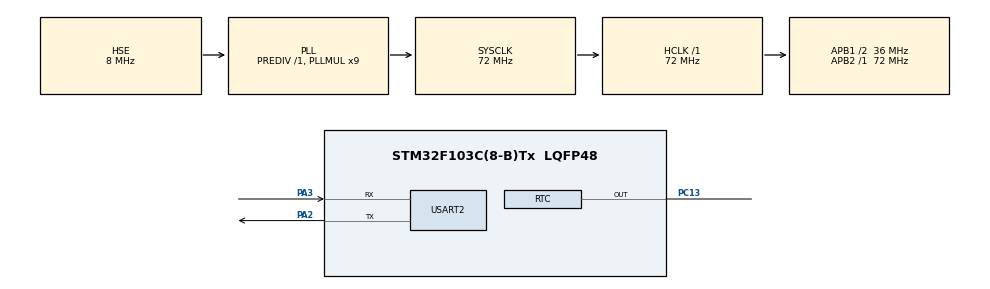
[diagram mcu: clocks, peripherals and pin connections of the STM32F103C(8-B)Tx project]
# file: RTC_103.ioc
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Mcu.Family=STM32F1
Mcu.Name=STM32F103C(8-B)Tx
Mcu.Package=LQFP48
NVIC.PriorityGroup=NVIC_PRIORITYGROUP_4
NVIC.RTC_Alarm_IRQn=true\:0\:0\:false\:false\:true\:true\:true
PA13.Mode=Serial_Wire
PA13.Signal=SYS_JTMS-SWDIO
PA14.Mode=Serial_Wire
PA14.Signal=SYS_JTCK-SWCLK
PA2.Mode=Asynchronous
PA2.Signal=USART2_TX
PA3.Mode=Asynchronous
PA3.Signal=USART2_RX
PC13-TAMPER-RTC.Mode=RTC OUT
PC13-TAMPER-RTC.Signal=RTC_OUT
PC14-OSC32_IN.Mode=LSE-External-Oscillator
PC14-OSC32_IN.Signal=RCC_OSC32_IN
PC15-OSC32_OUT.Mode=LSE-External-Oscillator
PC15-OSC32_OUT.Signal=RCC_OSC32_OUT
PD0-OSC_IN.Mode=HSE-External-Oscillator
PD0-OSC_IN.Signal=RCC_OSC_IN
PD1-OSC_OUT.Mode=HSE-External-Oscillator
PD1-OSC_OUT.Signal=RCC_OSC_OUT
ProjectManager.HeapSize=0x200
ProjectManager.StackSize=0x400
ProjectManager.TargetToolchain=STM32CubeIDE
RCC.AHBFreq_Value=72000000
RCC.APB1CLKDivider=RCC_HCLK_DIV2
RCC.APB1Freq_Value=36000000
RCC.APB1TimFreq_Value=72000000
RCC.APB2Freq_Value=72000000
RCC.APB2TimFreq_Value=72000000
RCC.HCLKFreq_Value=72000000
RCC.PLLMUL=RCC_PLL_MUL9
RCC.PLLSourceVirtual=RCC_PLLSOURCE_HSE
RCC.SYSCLKFreq_VALUE=72000000
RCC.SYSCLKSource=RCC_SYSCLKSOURCE_PLLCLK
RCC.USBFreq_Value=72000000
RTC.Date=21
RTC.Format=RTC_FORMAT_BIN
RTC.Hours=14
RTC.Hours_A-RTC\ OUT=14
RTC.Minutes=5
RTC.Minutes_A-RTC\ OUT=6
RTC.Month=RTC_MONTH_OCTOBER
RTC.OutPut=RTC_OUTPUTSOURCE_ALARM
RTC.Seconds=50
RTC.Seconds_A-RTC\ OUT=5
RTC.WeekDay=RTC_WEEKDAY_THURSDAY
RTC.Year=21
USART2.VirtualMode=VM_ASYNC
VP_RTC_VS_RTC_Activate.Mode=RTC_Enabled
VP_RTC_VS_RTC_Calendar.Mode=RTC_Calendar
board=custom

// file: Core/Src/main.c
/* USER CODE BEGIN Header */
/**
  ******************************************************************************
  * @file           : main.c
  * @brief          : Main program body
  ******************************************************************************
  * @attention
  *
  * <h2><center>&copy; Copyright (c) 2021 STMicroelectronics.
  * All rights reserved.</center></h2>
  *
  * This software component is licensed by ST under BSD 3-Clause license,
  * the "License"; You may not use this file except in compliance with the
  * License. You may obtain a copy of the License at:
  *                        opensource.org/licenses/BSD-3-Clause
  *
  ******************************************************************************
  */
/* USER CODE END Header */
#include "main.h"

/* USER CODE BEGIN Includes */
#include "stdio.h"
#include "string.h"

/* USER CODE END Includes */

RTC_HandleTypeDef hrtc;

UART_HandleTypeDef huart2;

/* USER CODE BEGIN PV */
RTC_TimeTypeDef sTime = {0};
RTC_DateTypeDef DateToUpdate = {0};

char trans_str[64] = {0,};

/* USER CODE END PV */

void SystemClock_Config(void);
static void MX_GPIO_Init(void);
static void MX_RTC_Init(void);
static void MX_USART2_UART_Init(void);

/* USER CODE BEGIN 0 */
void HAL_RTC_AlarmAEventCallback(RTC_HandleTypeDef *hrtc)
{
        snprintf(trans_str, 63, "ALARM\n");
        HAL_UART_Transmit(&huart2, (uint8_t*)trans_str, strlen(trans_str), 1000);
}
/* USER CODE END 0 */

int main(void)
{

  /* MCU Configuration--------------------------------------------------------*/

  /* Reset of all peripherals, Initializes the Flash interface and the Systick. */
  HAL_Init();

  /* Configure the system clock */
  SystemClock_Config();

  /* Initialize all configured peripherals */
  MX_GPIO_Init();
  MX_RTC_Init();
  MX_USART2_UART_Init();

  /* Infinite loop */
  while (1)
  {

    /* USER CODE BEGIN 3 */
      HAL_RTC_GetTime(&hrtc, &sTime, RTC_FORMAT_BIN); // RTC_FORMAT_BIN , RTC_FORMAT_BCD
      snprintf(trans_str, 63, "Time %d:%d:%d\n", sTime.Hours, sTime.Minutes, sTime.Seconds);
      HAL_UART_Transmit(&huart2, (uint8_t*)trans_str, strlen(trans_str), 1000);

      HAL_RTC_GetDate(&hrtc, &DateToUpdate, RTC_FORMAT_BIN);
      snprintf(trans_str, 63, "Date %d-%d-20%d\n", DateToUpdate.Date, DateToUpdate.Month, DateToUpdate.Year);
      HAL_UART_Transmit(&huart2, (uint8_t*)trans_str, strlen(trans_str), 1000);

      HAL_Delay(1000);

  }
  /* USER CODE END 3 */
}

void SystemClock_Config(void)
{
  RCC_OscInitTypeDef RCC_OscInitStruct = {0};
  RCC_ClkInitTypeDef RCC_ClkInitStruct = {0};
  RCC_PeriphCLKInitTypeDef PeriphClkInit = {0};

  /** Initializes the RCC Oscillators according to the specified parameters
  * in the RCC_OscInitTypeDef structure.
  */
  RCC_OscInitStruct.OscillatorType = RCC_OSCILLATORTYPE_LSI|RCC_OSCILLATORTYPE_HSE;
  RCC_OscInitStruct.HSEState = RCC_HSE_ON;
  RCC_OscInitStruct.HSEPredivValue = RCC_HSE_PREDIV_DIV1;
  RCC_OscInitStruct.HSIState = RCC_HSI_ON;
  RCC_OscInitStruct.LSIState = RCC_LSI_ON;
  RCC_OscInitStruct.PLL.PLLState = RCC_PLL_ON;
  RCC_OscInitStruct.PLL.PLLSource = RCC_PLLSOURCE_HSE;
  RCC_OscInitStruct.PLL.PLLMUL = RCC_PLL_MUL9;
  if (HAL_RCC_OscConfig(&RCC_OscInitStruct) != HAL_OK)
  {
    Error_Handler();
  }
  /** Initializes the CPU, AHB and APB buses clocks
  */
  RCC_ClkInitStruct.ClockType = RCC_CLOCKTYPE_HCLK|RCC_CLOCKTYPE_SYSCLK
                              |RCC_CLOCKTYPE_PCLK1|RCC_CLOCKTYPE_PCLK2;
  RCC_ClkInitStruct.SYSCLKSource = RCC_SYSCLKSOURCE_PLLCLK;
  RCC_ClkInitStruct.AHBCLKDivider = RCC_SYSCLK_DIV1;
  RCC_ClkInitStruct.APB1CLKDivider = RCC_HCLK_DIV2;
  RCC_ClkInitStruct.APB2CLKDivider = RCC_HCLK_DIV1;

  if (HAL_RCC_ClockConfig(&RCC_ClkInitStruct, FLASH_LATENCY_2) != HAL_OK)
  {
    Error_Handler();
  }
  PeriphClkInit.PeriphClockSelection = RCC_PERIPHCLK_RTC;
  PeriphClkInit.RTCClockSelection = RCC_RTCCLKSOURCE_LSI;
  if (HAL_RCCEx_PeriphCLKConfig(&PeriphClkInit) != HAL_OK)
  {
    Error_Handler();
  }
}

static void MX_RTC_Init(void)
{

  RTC_TimeTypeDef sTime = {0};
  RTC_DateTypeDef DateToUpdate = {0};
  RTC_AlarmTypeDef sAlarm = {0};

  /** Initialize RTC Only
  */
  hrtc.Instance = RTC;
  hrtc.Init.AsynchPrediv = RTC_AUTO_1_SECOND;
  hrtc.Init.OutPut = RTC_OUTPUTSOURCE_ALARM;
  if (HAL_RTC_Init(&hrtc) != HAL_OK)
  {
    Error_Handler();
  }

  /** Initialize RTC and set the Time and Date
  */
  sTime.Hours = 14;
  sTime.Minutes = 5;
  sTime.Seconds = 50;

  if (HAL_RTC_SetTime(&hrtc, &sTime, RTC_FORMAT_BIN) != HAL_OK)
  {
    Error_Handler();
  }
  DateToUpdate.WeekDay = RTC_WEEKDAY_THURSDAY;
  DateToUpdate.Month = RTC_MONTH_OCTOBER;
  DateToUpdate.Date = 21;
  DateToUpdate.Year = 21;

  if (HAL_RTC_SetDate(&hrtc, &DateToUpdate, RTC_FORMAT_BIN) != HAL_OK)
  {
    Error_Handler();
  }
  /** Enable the Alarm A
  */
  sAlarm.AlarmTime.Hours = 14;
  sAlarm.AlarmTime.Minutes = 6;
  sAlarm.AlarmTime.Seconds = 5;
  sAlarm.Alarm = RTC_ALARM_A;
  if (HAL_RTC_SetAlarm_IT(&hrtc, &sAlarm, RTC_FORMAT_BIN) != HAL_OK)
  {
    Error_Handler();
  }

}

static void MX_USART2_UART_Init(void)
{

  huart2.Instance = USART2;
  huart2.Init.BaudRate = 115200;
  huart2.Init.WordLength = UART_WORDLENGTH_8B;
  huart2.Init.StopBits = UART_STOPBITS_1;
  huart2.Init.Parity = UART_PARITY_NONE;
  huart2.Init.Mode = UART_MODE_TX_RX;
  huart2.Init.HwFlowCtl = UART_HWCONTROL_NONE;
  huart2.Init.OverSampling = UART_OVERSAMPLING_16;
  if (HAL_UART_Init(&huart2) != HAL_OK)
  {
    Error_Handler();
  }

}

static void MX_GPIO_Init(void)
{

  /* GPIO Ports Clock Enable */
  __HAL_RCC_GPIOC_CLK_ENABLE();
  __HAL_RCC_GPIOD_CLK_ENABLE();
  __HAL_RCC_GPIOA_CLK_ENABLE();

}

void Error_Handler(void)
{
  __disable_irq();
  while (1)
  {
  }
}

/************************ (C) COPYRIGHT STMicroelectronics *****END OF FILE****/
